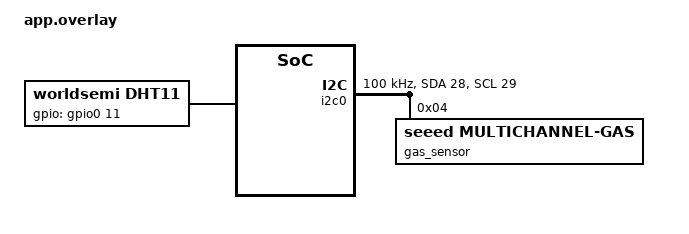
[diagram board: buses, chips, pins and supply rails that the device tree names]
/ {
    dht11_0: dht11@0 {
        compatible = "worldsemi,dht11";
        label = "DHT11";
        status = "okay";
        gpios = <&gpio0 11 GPIO_ACTIVE_HIGH>; /* DATA pin is connected to P0.11 */
    };

    aliases {
        dht11 = &dht11_0;
    };
};

&i2c0 {
    status = "okay";
    scl-pin = <29>;
    sda-pin = <28>;
    clock-frequency = <I2C_BITRATE_STANDARD>;
    gas_sensor: gas_sensor@4 {
        compatible = "seeed,multichannel-gas";
        reg = <0x04>;
    };
};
